# GD32VF103 register map
File version: 1.0
CPU: CM3 r2p1, little endian, no MPU, no FPU, 4 interrupt priority bits
Registers are 32-bit, read-write, reset 0x0 unless marked. A register's access mark holds for its fields unless they carry their own. Offsets are from the block's base; [hi:lo] are bit positions; {n}, {i} and the like mark numbered series; 'fields as' and 'values as' point back to an identical list.

## DMA0 — DMA controller
Base 0x40020000
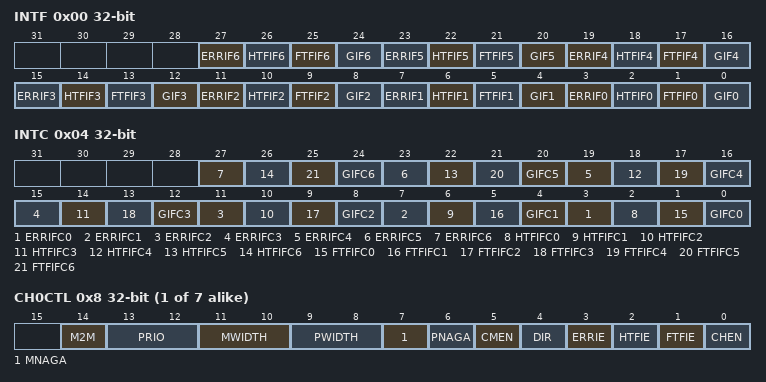
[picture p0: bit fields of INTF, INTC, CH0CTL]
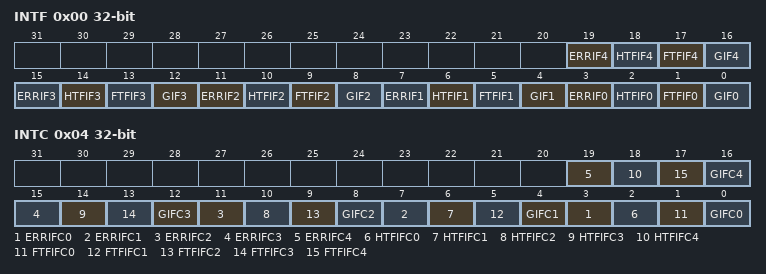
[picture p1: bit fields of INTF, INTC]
0x00 INTF ro — Interrupt flag register
  [4n+3] ERRIF{n} (n=0..6) — Error flag of channel {n}
  [4n+2] HTFIF{n} (n=0..6) — Half transfer finish flag of channel {n}
  [4n+1] FTFIF{n} (n=0..6) — Full Transfer finish flag of channe {n}
  [4n] GIF{n} (n=0..6) — Global interrupt flag of channel {n}
0x04 INTC wo — Interrupt flag clear register
  [4n+3] ERRIFC{n} (n=0..6) — Clear bit for error flag of channel {n}
  [4n+2] HTFIFC{n} (n=0..6) — Clear bit for half transfer finish flag of channel {n}
  [4n+1] FTFIFC{n} (n=0..6) — Clear bit for full transfer finish flag of channel {n}
  [4n] GIFC{n} (n=0..6) — Clear global interrupt flag of channel {n}
{0x8+0x14*i} CH{i}CTL (i=0..6) — Channel {i} control register
  [14] M2M — Memory to Memory Mode
  [13:12] PRIO — Priority level
  [11:10] MWIDTH — Transfer data size of memory
  [9:8] PWIDTH — Transfer data size of peripheral
  [7] MNAGA — Next address generation algorithm of memory
  [6] PNAGA — Next address generation algorithm of peripheral
  [5] CMEN — Circular mode enable
  [4] DIR — Transfer direction
  [3] ERRIE — Enable bit for channel error interrupt
  [2] HTFIE — Enable bit for channel half transfer finish interrupt
  [1] FTFIE — Enable bit for channel full transfer finish interrupt
  [0] CHEN — Channel enable
{0xC+0x14*i} CH{i}CNT (i=0..6) — Channel {i} counter register
  [15:0] CNT — Transfer counter
{0x10+0x14*i} CH{i}PADDR (i=0..6) — Channel {i} peripheral base address register
  [31:0] PADDR — Peripheral base address
{0x14+0x14*i} CH{i}MADDR (i=0..6) — Channel {i} memory base address register
  [31:0] MADDR — Memory base address

## DMA1 — Direct memory access controller
Base 0x40020000
Registers as DMA0, without CH5CTL, CH5CNT, CH5PADDR, CH5MADDR, CH6CTL, CH6CNT, CH6PADDR, CH6MADDR; these are added or differ:
0x00 INTF ro — Interrupt flag register
  [4n+3] ERRIF{n} (n=0..4) — Error flag of channel {n}
  [4n+2] HTFIF{n} (n=0..4) — Half transfer finish flag of channel {n}
  [4n+1] FTFIF{n} (n=0..4) — Full Transfer finish flag of channe {n}
  [4n] GIF{n} (n=0..4) — Global interrupt flag of channel {n}
0x04 INTC wo — Interrupt flag clear register
  [4n+3] ERRIFC{n} (n=0..4) — Clear bit for error flag of channel {n}
  [4n+2] HTFIFC{n} (n=0..4) — Clear bit for half transfer finish flag of channel {n}
  [4n+1] FTFIFC{n} (n=0..4) — Clear bit for full transfer finish flag of channel {n}
  [4n] GIFC{n} (n=0..4) — Clear global interrupt flag of channel {n}

## EXMC — External memory controller
Base 0xA0000000
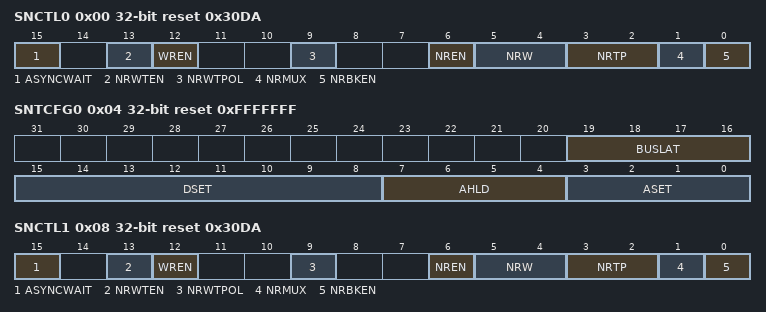
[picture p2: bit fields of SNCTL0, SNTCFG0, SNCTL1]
0x00 SNCTL0 reset 0x30DA — SRAM/NOR flash control register 0
  [15] ASYNCWAIT — Asynchronous wait
  [13] NRWTEN — NWAIT signal enable
  [12] WREN — Write enable
  [9] NRWTPOL — NWAIT signal polarity
  [6] NREN — NOR Flash access enable
  [5:4] NRW — NOR bank memory data bus width
  [3:2] NRTP — NOR bank memory type
  [1] NRMUX — NOR bank memory address/data multiplexing
  [0] NRBKEN — NOR bank enable
0x04 SNTCFG0 reset 0xFFFFFFF — SRAM/NOR flash timing configuration register 0
  [19:16] BUSLAT — Bus latency
  [15:8] DSET — Data setup time
  [7:4] AHLD — Address hold time
  [3:0] ASET — Address setup time
0x08 SNCTL1 reset 0x30DA — SRAM/NOR flash control register 1
  fields as SNCTL0

## EXTI — External interrupt/event controller
Base 0x40010400
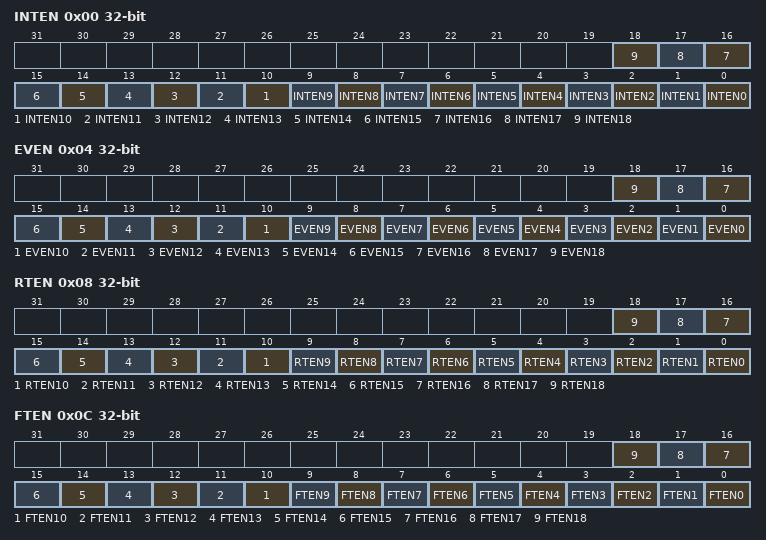
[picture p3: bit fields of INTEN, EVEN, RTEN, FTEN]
0x00 INTEN — Interrupt enable register (EXTI_INTEN)
  [n] INTEN{n} (n=0..18) — Enable Interrupt on line {n}
0x04 EVEN — Event enable register (EXTI_EVEN)
  [n] EVEN{n} (n=0..18) — Enable Event on line {n}
0x08 RTEN — Rising Edge Trigger Enable register (EXTI_RTEN)
  [n] RTEN{n} (n=0..18) — Rising edge trigger enable of line {n}
0x0C FTEN — Falling Egde Trigger Enable register (EXTI_FTEN)
  [n] FTEN{n} (n=0..18) — Falling edge trigger enable of line {n}
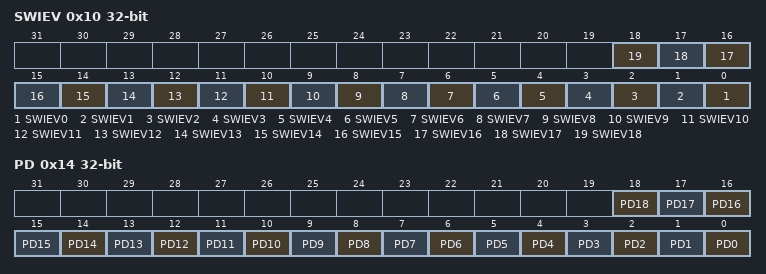
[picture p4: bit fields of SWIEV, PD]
0x10 SWIEV — Software interrupt event register (EXTI_SWIEV)
  [n] SWIEV{n} (n=0..18) — Interrupt/Event software trigger on line {n}
0x14 PD — Pending register (EXTI_PD)
  [n] PD{n} (n=0..18) — Interrupt pending status of line {n}
